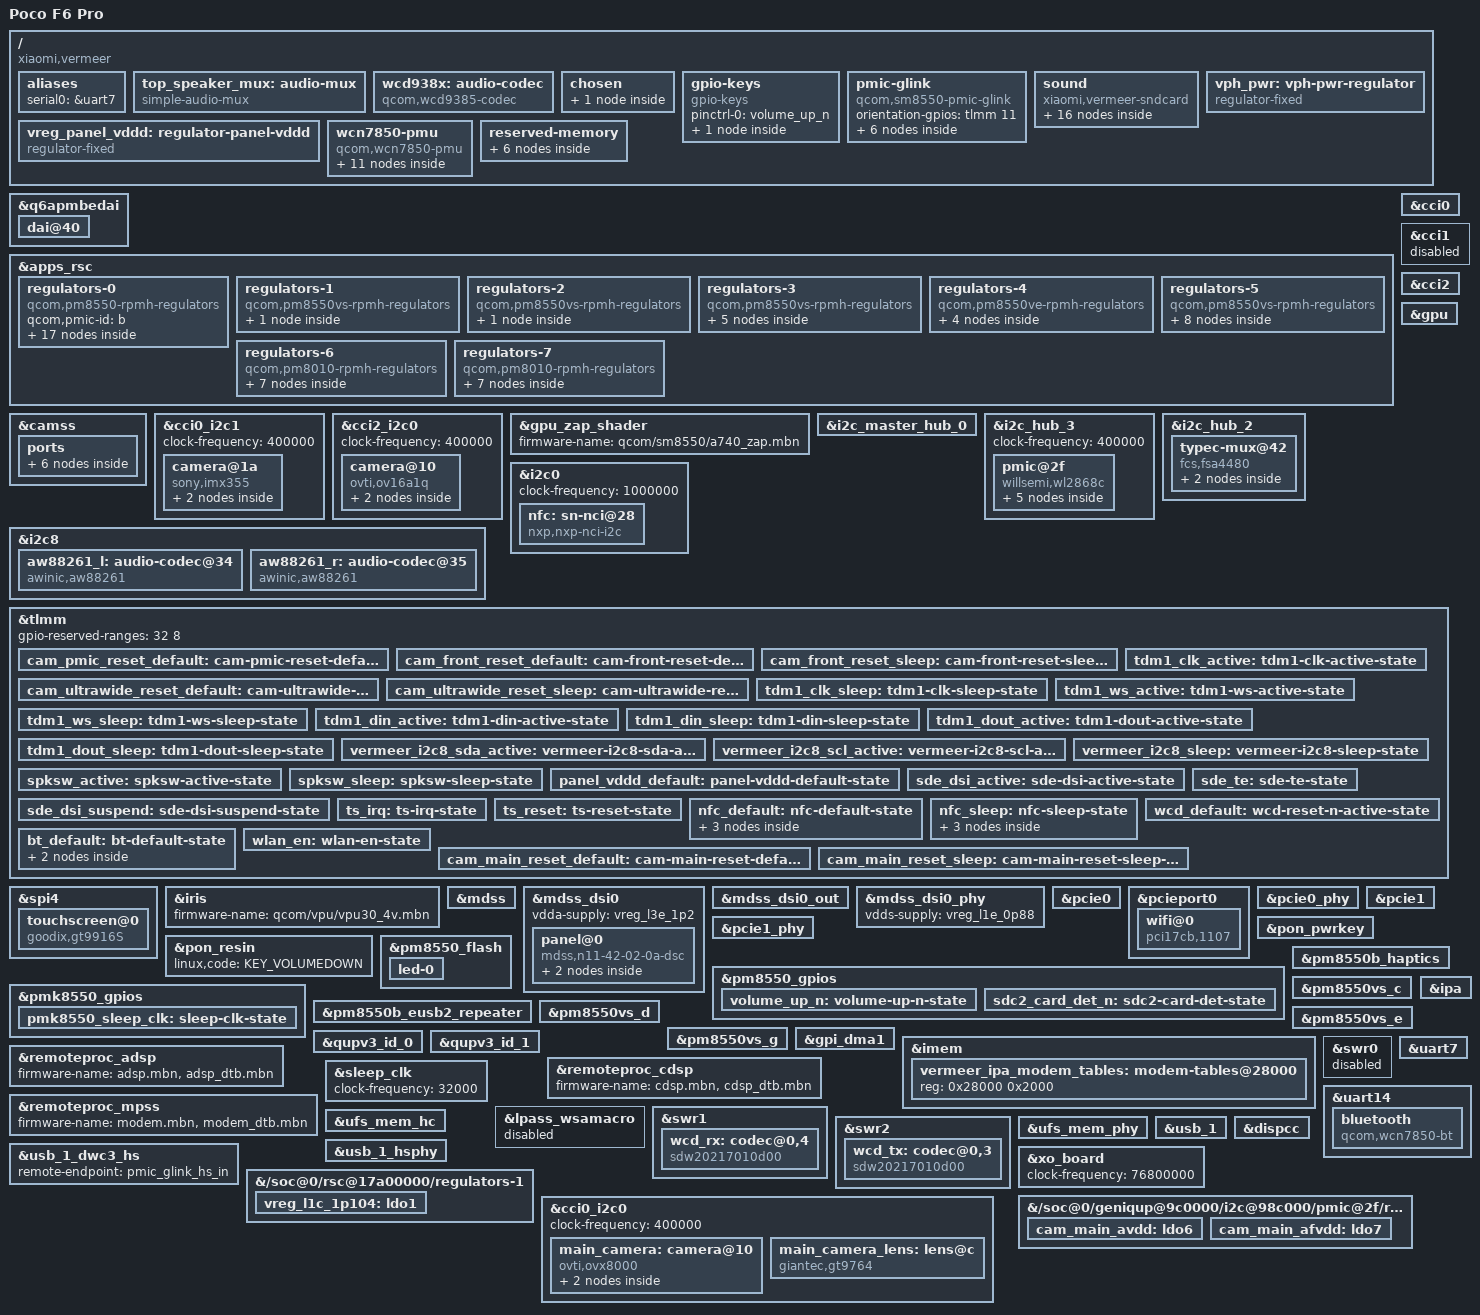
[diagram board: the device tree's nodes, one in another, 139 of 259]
// SPDX-License-Identifier: BSD-3-Clause
/*
 * Copyright (c) 2022, Linaro Limited
 */

/dts-v1/;

#include <dt-bindings/arm/qcom,ids.h>
#include <dt-bindings/clock/qcom,sm8550-camcc.h>
#include <dt-bindings/sound/qcom,q6dsp-lpass-ports.h>
#include <dt-bindings/regulator/qcom,rpmh-regulator.h>
#include "sm8550.dtsi"
#include "pm8010.dtsi"
#include "pm8550.dtsi"
#include "pm8550b.dtsi"
#define PMK8550VE_SID 5
#include "pm8550ve.dtsi"
#include "pm8550vs.dtsi"
#include "pmk8550.dtsi"
#include "pmr735d_a.dtsi"
#include "pmr735d_b.dtsi"
#include <dt-bindings/leds/common.h>
/delete-node/ &adspslpi_mem;

&q6apmbedai {
	#address-cells = <1>;
	#size-cells = <0>;

	dai@40 {
		reg = <SECONDARY_TDM_RX_0>;
		clocks = <&q6prmcc LPASS_CLK_ID_SEC_TDM_IBIT
			  LPASS_CLK_ATTRIBUTE_INVERT_COUPLE_NO>;
		clock-names = "bclk";

		qcom,tdm-sync-mode = <0>;
		qcom,tdm-sync-src = <1>;
		qcom,tdm-data-out = <1>;
		qcom,tdm-invert-sync = <0>;
		qcom,tdm-data-delay = <1>;
		qcom,tdm-data-align = <0>;
	};
};

/ {
	model = "Poco F6 Pro";
	compatible = "xiaomi,vermeer", "qcom,sm8550";
	chassis-type = "handset";

	qcom,msm-id = <QCOM_ID_SM8550 0x20000>;
	qcom,board-id = <0x10008 0>;

	aliases {
		serial0 = &uart7;
	};

	top_speaker_mux: audio-mux {
		compatible = "simple-audio-mux";
		mux-gpios = <&tlmm 68 GPIO_ACTIVE_HIGH>;
		sound-name-prefix = "Top Speaker";
		state-labels = "Speaker", "Receiver";
		idle-state = <0>;
	};

	wcd938x: audio-codec {
		compatible = "qcom,wcd9385-codec";

		pinctrl-names = "default";
		pinctrl-0 = <&wcd_default>;

		qcom,micbias1-microvolt = <2750000>;
		qcom,micbias2-microvolt = <2750000>;
		qcom,micbias3-microvolt = <2750000>;
		qcom,micbias4-microvolt = <2750000>;
		qcom,mbhc-buttons-vthreshold-microvolt = <75000 150000 237000 500000 500000 500000 500000 500000>;
		qcom,mbhc-headset-vthreshold-microvolt = <1700000>;
		qcom,mbhc-headphone-vthreshold-microvolt = <50000>;
		qcom,rx-device = <&wcd_rx>;
		qcom,tx-device = <&wcd_tx>;

		reset-gpios = <&tlmm 108 GPIO_ACTIVE_LOW>;

		vdd-buck-supply = <&vreg_l15b_1p8>;
		vdd-rxtx-supply = <&vreg_l15b_1p8>;
		vdd-io-supply = <&vreg_l15b_1p8>;
		vdd-mic-bias-supply = <&vreg_bob1>;

		#sound-dai-cells = <1>;
	};

	chosen {
		#address-cells = <2>;
		#size-cells = <2>;
		ranges;

		bootargs = "earlycon clk_ignore_unused pd_ignore_unused";
		stdout-path = "serial0:115200n8";

		framebuffer: framebuffer@b8000000 {
			compatible = "simple-framebuffer";
			reg = <0x0 0xb8000000 0x0 0x2b00000>;
			width = <1440>;
			height = <3200>;
			stride = <(1440 * 4)>;
			format = "a8r8g8b8";
		};

	};

	gpio-keys {
		compatible = "gpio-keys";

		pinctrl-0 = <&volume_up_n>;
		pinctrl-names = "default";

		key-volume-up {
			label = "Volume Up";
			linux,code = <KEY_VOLUMEUP>;
			gpios = <&pm8550_gpios 6 GPIO_ACTIVE_LOW>;
			debounce-interval = <32>;
			linux,can-disable;
			wakeup-source;
		};
	};

	pmic-glink {
		compatible = "qcom,sm8550-pmic-glink", "qcom,pmic-glink";
		#address-cells = <1>;
		#size-cells = <0>;
		orientation-gpios = <&tlmm 11 GPIO_ACTIVE_HIGH>;

		connector@0 {
			compatible = "usb-c-connector";
			reg = <0>;
			power-role = "dual";
			data-role = "dual";

			ports {
				#address-cells = <1>;
				#size-cells = <0>;

				port@0 {
					reg = <0>;

					pmic_glink_hs_in: endpoint {
						remote-endpoint = <&usb_1_dwc3_hs>;
					};
				};

				port@2 {
					reg = <2>;

					pmic_glink_sbu: endpoint {
						remote-endpoint = <&fsa4480_sbu_mux>;
					};
				};
			};
		};
	};

	sound {
		compatible = "xiaomi,vermeer-sndcard", "qcom,sm8550-sndcard",
			     "qcom,sm8450-sndcard";
		model = "SM8550-VERMEER";
		aux-devs = <&top_speaker_mux>;
		pinctrl-names = "default", "sleep";
		pinctrl-0 = <&tdm1_clk_active &tdm1_ws_active
				     &tdm1_din_active &tdm1_dout_active
				     &spksw_active>;
		pinctrl-1 = <&tdm1_clk_sleep &tdm1_ws_sleep
				     &tdm1_din_sleep &tdm1_dout_sleep
				     &spksw_sleep>;

		widgets = "Speaker", "Top Speaker",
			  "Speaker", "Bottom Speaker";
		audio-routing = "Top Speaker", "Top Speaker OUT",
				"Top Speaker IN1", "Amplifier L DAC Output",
				"Top Speaker IN2", "Amplifier L DAC Output",
				"Bottom Speaker", "Amplifier R DAC Output",
				"IN1_HPHL", "HPHL_OUT",
				"IN2_HPHR", "HPHR_OUT",
				"AMIC1", "MIC BIAS1",
				"AMIC2", "MIC BIAS2",
				"AMIC3", "MIC BIAS3",
				"AMIC4", "MIC BIAS3",
				"AMIC5", "MIC BIAS4",
				"VA DMIC0", "MIC BIAS1",
				"VA DMIC1", "MIC BIAS1",
				"VA DMIC2", "MIC BIAS3",
				"TX DMIC0", "MIC BIAS1",
				"TX DMIC1", "MIC BIAS2",
				"TX DMIC2", "MIC BIAS3",
				"TX SWR_INPUT0", "ADC1_OUTPUT";

		wcd-playback-dai-link {
			link-name = "WCD Playback";

			cpu {
				sound-dai = <&q6apmbedai RX_CODEC_DMA_RX_0>;
			};

			codec {
				sound-dai = <&wcd938x 0>, <&swr1 0>, <&lpass_rxmacro 0>;
			};

			platform {
				sound-dai = <&q6apm>;
			};
		};

		wcd-capture-dai-link {
			link-name = "WCD Capture";

			cpu {
				sound-dai = <&q6apmbedai TX_CODEC_DMA_TX_3>;
			};

			codec {
				sound-dai = <&wcd938x 1>, <&swr2 0>, <&lpass_txmacro 0>;
			};

			platform {
				sound-dai = <&q6apm>;
			};
		};

		aif-speakers-dai-link {
			link-name = "Secondary TDM0 Playback";

			cpu {
				sound-dai = <&q6apmbedai SECONDARY_TDM_RX_0>;
			};

			codec {
				sound-dai = <&aw88261_r>, <&aw88261_l>;
			};

			platform {
				sound-dai = <&q6apm>;
			};
		};

		va-dai-link {
			link-name = "VA Capture";

			cpu {
				sound-dai = <&q6apmbedai VA_CODEC_DMA_TX_0>;
			};

			codec {
				sound-dai = <&lpass_vamacro 0>;
			};

			platform {
				sound-dai = <&q6apm>;
			};
		};
	};

	vreg_panel_vddd: regulator-panel-vddd {
		compatible = "regulator-fixed";
		regulator-name = "vreg_panel_vddd";
		regulator-min-microvolt = <1070000>;
		regulator-max-microvolt = <1070000>;

		pinctrl-names = "default";
		pinctrl-0 = <&panel_vddd_default>;

		gpio = <&tlmm 42 GPIO_ACTIVE_HIGH>;
		enable-active-high;
		regulator-boot-on;
	};

	vph_pwr: vph-pwr-regulator {
		compatible = "regulator-fixed";
		regulator-name = "vph_pwr";
		regulator-min-microvolt = <3700000>;
		regulator-max-microvolt = <3700000>;

		regulator-always-on;
		regulator-boot-on;
	};

	wcn7850-pmu {
		compatible = "qcom,wcn7850-pmu";

		pinctrl-names = "default";
		pinctrl-0 = <&wlan_en>, <&bt_default>, <&pmk8550_sleep_clk>;

		wlan-enable-gpios = <&tlmm 80 GPIO_ACTIVE_HIGH>;
		bt-enable-gpios = <&tlmm 81 GPIO_ACTIVE_HIGH>;

		vdd-supply = <&vreg_s5g_0p8>;
		vddio-supply = <&vreg_l15b_1p8>;
		vddaon-supply = <&vreg_s2g_0p8>;
		vdddig-supply = <&vreg_s4e_0p9>;
		vddrfa1p2-supply = <&vreg_s4g_1p3>;
		vddrfa1p8-supply = <&vreg_s6g_1p8>;

		regulators {
			vreg_pmu_rfa_cmn: ldo0 {
				regulator-name = "vreg_pmu_rfa_cmn";
			};

			vreg_pmu_aon_0p59: ldo1 {
				regulator-name = "vreg_pmu_aon_0p59";
			};

			vreg_pmu_wlcx_0p8: ldo2 {
				regulator-name = "vreg_pmu_wlcx_0p8";
			};

			vreg_pmu_wlmx_0p85: ldo3 {
				regulator-name = "vreg_pmu_wlmx_0p85";
			};

			vreg_pmu_btcmx_0p85: ldo4 {
				regulator-name = "vreg_pmu_btcmx_0p85";
			};

			vreg_pmu_rfa_0p8: ldo5 {
				regulator-name = "vreg_pmu_rfa_0p8";
			};

			vreg_pmu_rfa_1p2: ldo6 {
				regulator-name = "vreg_pmu_rfa_1p2";
			};

			vreg_pmu_rfa_1p8: ldo7 {
				regulator-name = "vreg_pmu_rfa_1p8";
			};

			vreg_pmu_pcie_0p9: ldo8 {
				regulator-name = "vreg_pmu_pcie_0p9";
			};

			vreg_pmu_pcie_1p8: ldo9 {
				regulator-name = "vreg_pmu_pcie_1p8";
			};
		};
	};

	reserved-memory {

		ramoops@a7000000 {
			compatible = "ramoops";
			reg = <0x0 0xa7000000 0x0 0x400000>;
			console-size = <0x200000>;
			pmsg-size = <0x200000>;
		};

		xbl_dt_log_mem: xbl_dt_log@81a00000 {
			reg = <0x0 0x81a00000 0x0 0x40000>;
			no-map;
		};

		aop_image_mem: aop_image_region@81c00000 {
			reg = <0x0 0x81c00000 0x0 0x60000>;
			no-map;
		};

		xbl_ramdump_mem: xbl_ramdump_region@81200000 {
			reg = <0x0 0x81200000 0x0 0x280000>;
			no-map;
		};

		adspslpi_mem: adspslpi_region@9ea00000 {
			reg = <0x0 0x9ea00000 0x0 0x4680000>;
			no-map;
		};

		splash_memory: splash_region@b8000000 {
			reg = <0x0 0xb8000000 0x0 0x2b00000>;
			no-map;
		};

	};
};

&apps_rsc {
	regulators-0 {
		compatible = "qcom,pm8550-rpmh-regulators";
		qcom,pmic-id = "b";

		// vdd-bob1-supply = <&vph_pwr>;
		// vdd-bob2-supply = <&vph_pwr>;
		// vdd-l1-l4-l10-supply = <&vreg_s6g_1p8>;
		// vdd-l2-l13-l14-supply = <&vreg_bob1>;
		// vdd-l3-supply = <&vreg_s4g_1p3>;
		// vdd-l5-l16-supply = <&vreg_bob1>;
		// vdd-l6-l7-supply = <&vreg_bob1>;
		// vdd-l8-supply = <&vreg_bob1>;
		// vdd-l11-supply = <&vreg_s4g_1p3>;
		// vdd-l12-supply = <&vreg_s6g_1p8>;
		// vdd-l15-supply = <&vreg_s6g_1p8>;
		// vdd-l17-supply = <&vreg_bob2>;

		vreg_bob1: bob1 {
			regulator-name = "vreg_bob1";
			regulator-min-microvolt = <3296000>;
			regulator-max-microvolt = <3960000>;
			regulator-initial-mode = <RPMH_REGULATOR_MODE_HPM>;
		};

		vreg_bob2: bob2 {
			regulator-name = "vreg_bob2";
			regulator-min-microvolt = <2720000>;
			regulator-max-microvolt = <3008000>;
			regulator-initial-mode = <RPMH_REGULATOR_MODE_HPM>;
		};

		vreg_l1b_1p8: ldo1 {
			regulator-name = "vreg_l1b_1p8";
			regulator-min-microvolt = <1800000>;
			regulator-max-microvolt = <1800000>;
			regulator-initial-mode = <RPMH_REGULATOR_MODE_HPM>;
		};

		vreg_l2b_3p0: ldo2 {
			regulator-name = "vreg_l2b_3p0";
			regulator-min-microvolt = <3200000>;
			regulator-max-microvolt = <3200000>;
			regulator-initial-mode = <RPMH_REGULATOR_MODE_HPM>;
		};

		vreg_l4b_3p1: ldo4 {
			regulator-name = "vreg_l4b_1p8";
			regulator-min-microvolt = <1800000>;
			regulator-max-microvolt = <1800000>;
			regulator-initial-mode = <RPMH_REGULATOR_MODE_HPM>;
		};

		vreg_l5b_3p1: ldo5 {
			regulator-name = "vreg_l5b_3p1";
			regulator-min-microvolt = <3104000>;
			regulator-max-microvolt = <3104000>;
			regulator-initial-mode = <RPMH_REGULATOR_MODE_HPM>;
		};

		vreg_l6b_1p8: ldo6 {
			regulator-name = "vreg_l6b_1p8";
			regulator-min-microvolt = <1800000>;
			regulator-max-microvolt = <3008000>;
			regulator-initial-mode = <RPMH_REGULATOR_MODE_HPM>;
		};

		vreg_l7b_1p8: ldo7 {
			regulator-name = "vreg_l7b_1p8";
			regulator-min-microvolt = <1800000>;
			regulator-max-microvolt = <3008000>;
			regulator-initial-mode = <RPMH_REGULATOR_MODE_HPM>;
		};

		vreg_l8b_1p8: ldo8 {
			regulator-name = "vreg_l8b_1p8";
			regulator-min-microvolt = <1800000>;
			regulator-max-microvolt = <1800000>;
			regulator-initial-mode = <RPMH_REGULATOR_MODE_HPM>;
		};

		vreg_l9b_2p9: ldo9 {
			regulator-name = "vreg_l9b_2p9";
			regulator-min-microvolt = <2960000>;
			regulator-max-microvolt = <3300000>;
			regulator-initial-mode = <RPMH_REGULATOR_MODE_HPM>;
			regulator-boot-on;
			regulator-always-on;
		};

		vreg_l11b_1p2: ldo11 {
			regulator-name = "vreg_l11b_1p2";
			regulator-min-microvolt = <1140000>;
			regulator-max-microvolt = <1144000>;
			regulator-initial-mode = <RPMH_REGULATOR_MODE_HPM>;
		};

		vreg_l12b_1p8: ldo12 {
			regulator-name = "vreg_l12b_1p8";
			regulator-min-microvolt = <1800000>;
			regulator-max-microvolt = <1800000>;
			regulator-initial-mode = <RPMH_REGULATOR_MODE_HPM>;
		};

		vreg_l13b_3p0: ldo13 {
			regulator-name = "vreg_l13b_3p0";
			regulator-min-microvolt = <3000000>;
			regulator-max-microvolt = <3000000>;
			regulator-initial-mode = <RPMH_REGULATOR_MODE_HPM>;
		};

		vreg_l14b_3p2: ldo14 {
			regulator-name = "vreg_l14b_3p2";
			regulator-min-microvolt = <3200000>;
			regulator-max-microvolt = <3200000>;
			regulator-initial-mode = <RPMH_REGULATOR_MODE_HPM>;
		};

		vreg_l15b_1p8: ldo15 {
			regulator-name = "vreg_l15b_1p8";
			regulator-min-microvolt = <1800000>;
			regulator-max-microvolt = <1800000>;
			regulator-initial-mode = <RPMH_REGULATOR_MODE_HPM>;
		};

		vreg_l16b_2p8: ldo16 {
			regulator-name = "vreg_l16b_2p8";
			regulator-min-microvolt = <3104000>;
			regulator-max-microvolt = <3104000>;
			regulator-initial-mode = <RPMH_REGULATOR_MODE_HPM>;
		};

		vreg_l17b_2p5: ldo17 {
			regulator-name = "vreg_l17b_2p5";
			regulator-min-microvolt = <2504000>;
			regulator-max-microvolt = <2504000>;
			regulator-initial-mode = <RPMH_REGULATOR_MODE_HPM>;
		};
	};

	regulators-1 {
		compatible = "qcom,pm8550vs-rpmh-regulators";
		qcom,pmic-id = "c";

		vdd-l3-supply = <&vreg_s4e_0p9>;

		vreg_l3c_0p91: ldo3 {
			regulator-name = "vreg_l3c_0p9";
			regulator-min-microvolt = <880000>;
			regulator-max-microvolt = <912000>;
			regulator-initial-mode = <RPMH_REGULATOR_MODE_HPM>;
		};
	};

	regulators-2 {
		compatible = "qcom,pm8550vs-rpmh-regulators";
		qcom,pmic-id = "d";

		vdd-l1-supply = <&vreg_s4e_0p9>;

		vreg_l1d_0p88: ldo1 {
			regulator-name = "vreg_l1d_0p88";
			regulator-min-microvolt = <912000>;
			regulator-max-microvolt = <920000>;
			regulator-initial-mode = <RPMH_REGULATOR_MODE_HPM>;
		};
	};

	regulators-3 {
		compatible = "qcom,pm8550vs-rpmh-regulators";
		qcom,pmic-id = "e";

		vdd-l1-supply = <&vreg_s4e_0p9>;
		vdd-l2-supply = <&vreg_s4e_0p9>;
		vdd-l3-supply = <&vreg_s4g_1p3>;
		vdd-s4-supply = <&vph_pwr>;
		vdd-s5-supply = <&vph_pwr>;

		vreg_s4e_0p9: smps4 {
			regulator-name = "vreg_s4e_0p9";
			regulator-min-microvolt = <904000>;
			regulator-max-microvolt = <984000>;
			regulator-initial-mode = <RPMH_REGULATOR_MODE_HPM>;
		};

		vreg_s5e_1p1: smps5 {
			regulator-name = "vreg_s5e_1p1";
			regulator-min-microvolt = <1010000>;
			regulator-max-microvolt = <1120000>;
			regulator-initial-mode = <RPMH_REGULATOR_MODE_HPM>;
		};

		vreg_l1e_0p88: ldo1 {
			regulator-name = "vreg_l1e_0p88";
			regulator-min-microvolt = <880000>;
			regulator-max-microvolt = <912000>;
			regulator-initial-mode = <RPMH_REGULATOR_MODE_HPM>;
		};

		vreg_l2e_0p9: ldo2 {
			regulator-name = "vreg_l2e_0p9";
			regulator-min-microvolt = <870000>;
			regulator-max-microvolt = <970000>;
			regulator-initial-mode = <RPMH_REGULATOR_MODE_HPM>;
		};

		vreg_l3e_1p2: ldo3 {
			regulator-name = "vreg_l3e_1p2";
			regulator-min-microvolt = <1200000>;
			regulator-max-microvolt = <1200000>;
			regulator-initial-mode = <RPMH_REGULATOR_MODE_HPM>;
		};
	};

	regulators-4 {
		compatible = "qcom,pm8550ve-rpmh-regulators";
		qcom,pmic-id = "f";

		vdd-l1-supply = <&vreg_s4e_0p9>;
		vdd-l2-supply = <&vreg_s4e_0p9>;
		vdd-l3-supply = <&vreg_s4e_0p9>;
		vdd-s4-supply = <&vph_pwr>;

		vreg_s4f_0p5: smps4 {
			regulator-name = "vreg_s4f_0p5";
			regulator-min-microvolt = <300000>;
			regulator-max-microvolt = <700000>;
			regulator-initial-mode = <RPMH_REGULATOR_MODE_HPM>;
		};

		vreg_l1f_0p9: ldo1 {
			regulator-name = "vreg_l1f_0p9";
			regulator-min-microvolt = <880000>;
			regulator-max-microvolt = <912000>;
			regulator-initial-mode = <RPMH_REGULATOR_MODE_HPM>;
		};

		vreg_l2f_0p88: ldo2 {
			regulator-name = "vreg_l2f_0p88";
			regulator-min-microvolt = <880000>;
			regulator-max-microvolt = <912000>;
			regulator-initial-mode = <RPMH_REGULATOR_MODE_HPM>;
		};

		vreg_l3f_0p91: ldo3 {
			regulator-name = "vreg_l3f_0p91";
			regulator-min-microvolt = <880000>;
			regulator-max-microvolt = <912000>;
			regulator-initial-mode = <RPMH_REGULATOR_MODE_HPM>;
		};
	};

	regulators-5 {
		compatible = "qcom,pm8550vs-rpmh-regulators";
		qcom,pmic-id = "g";

		vdd-l1-supply = <&vreg_s4g_1p3>;
		vdd-l2-supply = <&vreg_s4g_1p3>;
		vdd-l3-supply = <&vreg_s4g_1p3>;
		vdd-s1-supply = <&vph_pwr>;
		vdd-s2-supply = <&vph_pwr>;
		vdd-s3-supply = <&vph_pwr>;
		vdd-s4-supply = <&vph_pwr>;
		vdd-s5-supply = <&vph_pwr>;
		vdd-s6-supply = <&vph_pwr>;

		vreg_s1g_1p2: smps1 {
			regulator-name = "vreg_s1g_1p2";
			regulator-min-microvolt = <1200000>;
			regulator-max-microvolt = <1300000>;
			regulator-initial-mode = <RPMH_REGULATOR_MODE_HPM>;
		};

		vreg_s2g_0p8: smps2 {
			regulator-name = "vreg_s2g_0p8";
			regulator-min-microvolt = <500000>;
			regulator-max-microvolt = <1036000>;
			regulator-initial-mode = <RPMH_REGULATOR_MODE_HPM>;
		};

		vreg_s4g_1p3: smps4 {
			regulator-name = "vreg_s4g_1p3";
			regulator-min-microvolt = <1200000>;
			regulator-max-microvolt = <1352000>;
			regulator-initial-mode = <RPMH_REGULATOR_MODE_HPM>;
		};

		vreg_s5g_0p8: smps5 {
			regulator-name = "vreg_s5g_0p8";
			regulator-min-microvolt = <500000>;
			regulator-max-microvolt = <1004000>;
			regulator-initial-mode = <RPMH_REGULATOR_MODE_HPM>;
		};

		vreg_s6g_1p8: smps6 {
			regulator-name = "vreg_s6g_1p8";
			regulator-min-microvolt = <1800000>;
			regulator-max-microvolt = <2000000>;
			regulator-initial-mode = <RPMH_REGULATOR_MODE_HPM>;
		};

		vreg_l1g_1p2: ldo1 {
			regulator-name = "vreg_l1g_1p2";
			regulator-min-microvolt = <1144000>;
			regulator-max-microvolt = <1256000>;
			regulator-initial-mode = <RPMH_REGULATOR_MODE_HPM>;
		};

		vreg_l2g_1p2: ldo2 {
			regulator-name = "vreg_l2g_1p2";
			regulator-min-microvolt = <1100000>;
			regulator-max-microvolt = <1200000>;
			regulator-initial-mode = <RPMH_REGULATOR_MODE_HPM>;
		};

		vreg_l3g_1p2: ldo3 {
			regulator-name = "vreg_l3g_1p2";
			regulator-min-microvolt = <1200000>;
			regulator-max-microvolt = <1200000>;
			regulator-initial-mode = <RPMH_REGULATOR_MODE_HPM>;
		};
	};

	regulators-6 {
		compatible = "qcom,pm8010-rpmh-regulators";
		qcom,pmic-id = "m";

		vdd-l1-l2-supply = <&vreg_s4g_1p3>;
		vdd-l3-l4-supply = <&vreg_bob2>;
		vdd-l5-supply = <&vreg_s6g_1p8>;
		vdd-l6-supply = <&vreg_s6g_1p8>;
		vdd-l7-supply = <&vreg_bob1>;

		vreg_l1m_1p056: ldo1 {
			regulator-name = "vreg_l1m_1p056";
			regulator-min-microvolt = <1056000>;
			regulator-max-microvolt = <1056000>;
			regulator-initial-mode = <RPMH_REGULATOR_MODE_HPM>;
		};

		vreg_l2m_1p056: ldo2 {
			regulator-name = "vreg_l2m_1p056";
			regulator-min-microvolt = <1056000>;
			regulator-max-microvolt = <1056000>;
			regulator-initial-mode = <RPMH_REGULATOR_MODE_HPM>;
		};

		vreg_l3m_2p8: ldo3 {
			regulator-name = "vreg_l3m_2p8";
			regulator-min-microvolt = <2800000>;
			regulator-max-microvolt = <2800000>;
			regulator-initial-mode = <RPMH_REGULATOR_MODE_HPM>;
		};

		vreg_l4m_2p8: ldo4 {
			regulator-name = "vreg_l4m_2p8";
			regulator-min-microvolt = <2800000>;
			regulator-max-microvolt = <2800000>;
			regulator-initial-mode = <RPMH_REGULATOR_MODE_HPM>;
		};

		vreg_l5m_1p8: ldo5 {
			regulator-name = "vreg_l5m_1p8";
			regulator-min-microvolt = <1800000>;
			regulator-max-microvolt = <1800000>;
			regulator-initial-mode = <RPMH_REGULATOR_MODE_HPM>;
		};

		vreg_l6m_1p8: ldo6 {
			regulator-name = "vreg_l6m_1p8";
			regulator-min-microvolt = <1800000>;
			regulator-max-microvolt = <1800000>;
			regulator-initial-mode = <RPMH_REGULATOR_MODE_HPM>;
		};

		vreg_l7m_2p9: ldo7 {
			regulator-name = "vreg_l7m_2p9";
			regulator-min-microvolt = <2800000>;
			regulator-max-microvolt = <2904000>;
			regulator-initial-mode = <RPMH_REGULATOR_MODE_HPM>;
		};
	};

	regulators-7 {
		compatible = "qcom,pm8010-rpmh-regulators";
		qcom,pmic-id = "n";

		vdd-l1-l2-supply = <&vreg_s4g_1p3>;
		vdd-l3-l4-supply = <&vreg_bob2>;
		vdd-l5-supply = <&vreg_s6g_1p8>;
		vdd-l6-supply = <&vreg_bob1>;
		vdd-l7-supply = <&vreg_bob1>;

		vreg_l1n_1p1: ldo1 {
			regulator-name = "vreg_l1n_1p1";
			regulator-min-microvolt = <1104000>;
			regulator-max-microvolt = <1104000>;
			regulator-initial-mode = <RPMH_REGULATOR_MODE_HPM>;
		};

		vreg_l2n_1p1: ldo2 {
			regulator-name = "vreg_l2n_1p1";
			regulator-min-microvolt = <1104000>;
			regulator-max-microvolt = <1104000>;
			regulator-initial-mode = <RPMH_REGULATOR_MODE_HPM>;
		};

		vreg_l3n_2p8: ldo3 {
			regulator-name = "vreg_l3n_2p8";
			regulator-min-microvolt = <2800000>;
			regulator-max-microvolt = <2800000>;
			regulator-initial-mode = <RPMH_REGULATOR_MODE_HPM>;
		};

		vreg_l4n_2p8: ldo4 {
			regulator-name = "vreg_l4n_2p8";
			regulator-min-microvolt = <2800000>;
			regulator-max-microvolt = <2800000>;
			regulator-initial-mode = <RPMH_REGULATOR_MODE_HPM>;
		};

		vreg_l5n_1p8: ldo5 {
			regulator-name = "vreg_l5n_1p8";
			regulator-min-microvolt = <1800000>;
			regulator-max-microvolt = <1800000>;
			regulator-initial-mode = <RPMH_REGULATOR_MODE_HPM>;
		};

		vreg_l6n_3p3: ldo6 {
			regulator-name = "vreg_l6n_3p3";
			regulator-min-microvolt = <3304000>;
			regulator-max-microvolt = <3304000>;
			regulator-initial-mode = <RPMH_REGULATOR_MODE_HPM>;
		};

		vreg_l7n_2p96: ldo7 {
			regulator-name = "vreg_l7n_2p96";
			regulator-min-microvolt = <2960000>;
			regulator-max-microvolt = <2960000>;
			regulator-initial-mode = <RPMH_REGULATOR_MODE_HPM>;
		};
	};
};

&camss {
	vdda-phy-supply = <&vreg_l1e_0p88>;
	vdda-pll-supply = <&vreg_l3e_1p2>;
	status = "okay";

	ports {
		port@2 {
			reg = <2>;

			csiphy2_ep: endpoint {
				clock-lanes = <4>;
				data-lanes = <0 1 2 3>;
				remote-endpoint = <&imx355_ep>;
			};
		};

		port@4 {
			reg = <4>;

			csiphy4_ep: endpoint {
				clock-lanes = <4>;
				data-lanes = <0 1 2 3>;
				remote-endpoint = <&ov16a1q_ep>;
			};
		};
	};
};

&cci0 {
	pinctrl-0 = <&cci0_1_default>;
	pinctrl-1 = <&cci0_1_sleep>;
	status = "okay";
};

&cci0_i2c1 {
	clock-frequency = <400000>;

	camera@1a {
		compatible = "sony,imx355";
		reg = <0x1a>;

		clocks = <&camcc CAM_CC_MCLK1_CLK>;
		assigned-clocks = <&camcc CAM_CC_MCLK1_CLK>;
		assigned-clock-rates = <19200000>;

		reset-gpios = <&tlmm 117 GPIO_ACTIVE_LOW>;
		pinctrl-names = "default", "sleep";
		pinctrl-0 = <&cam1_default &cam_ultrawide_reset_default>;
		pinctrl-1 = <&cam1_sleep &cam_ultrawide_reset_sleep>;

		avdd-supply = <&cam_ultrawide_avdd>;
		dvdd-supply = <&cam_ultrawide_dvdd>;
		dovdd-supply = <&vreg_l8b_1p8>;

		orientation = <1>;
		rotation = <270>;

		port {
			imx355_ep: endpoint {
				data-lanes = <1 2 3 4>;
				link-frequencies = /bits/ 64 <360000000>;
				remote-endpoint = <&csiphy2_ep>;
			};
		};
	};
};

&cci1 {
	status = "disabled";
};

&cci2 {
	pinctrl-0 = <&cci2_0_default>;
	pinctrl-1 = <&cci2_0_sleep>;
	status = "okay";
};

&cci2_i2c0 {
	clock-frequency = <400000>;

	camera@10 {
		compatible = "ovti,ov16a1q";
		reg = <0x10>;

		clocks = <&camcc CAM_CC_MCLK0_CLK>;
		assigned-clocks = <&camcc CAM_CC_MCLK0_CLK>;
		assigned-clock-rates = <19200000>;

		reset-gpios = <&tlmm 120 GPIO_ACTIVE_LOW>;
		pinctrl-names = "default", "sleep";
		pinctrl-0 = <&cam0_default &cam_front_reset_default>;
		pinctrl-1 = <&cam0_sleep &cam_front_reset_sleep>;

		avdd-supply = <&cam_front_avdd>;
		dvdd-supply = <&cam_front_dvdd>;
		dovdd-supply = <&vreg_l8b_1p8>;
		orientation = <0>;
		rotation = <90>;

		port {
			ov16a1q_ep: endpoint {
				data-lanes = <1 2 3 4>;
				link-frequencies = /bits/ 64 <696000000>;
				remote-endpoint = <&csiphy4_ep>;
			};
		};
	};
};

&gpu {
	status = "okay";
};

&gpu_zap_shader {
	firmware-name = "qcom/sm8550/a740_zap.mbn";
};

&i2c_master_hub_0 {
	status = "okay";
};

&i2c_hub_3 {
	clock-frequency = <400000>;
	status = "okay";

	pmic@2f {
		compatible = "willsemi,wl2868c";
		reg = <0x2f>;
		reset-gpios = <&tlmm 126 GPIO_ACTIVE_LOW>;
		pinctrl-names = "default";
		pinctrl-0 = <&cam_pmic_reset_default>;

		regulators {
			cam_front_dvdd: ldo1 {
				regulator-name = "cam_front_dvdd";
				regulator-min-microvolt = <1200000>;
				regulator-max-microvolt = <1200000>;
			};

			cam_ultrawide_dvdd: ldo2 {
				regulator-name = "cam_ultrawide_dvdd";
				regulator-min-microvolt = <1200000>;
				regulator-max-microvolt = <1200000>;
			};

			cam_ultrawide_avdd: ldo3 {
				regulator-name = "cam_ultrawide_avdd";
				regulator-min-microvolt = <2700000>;
				regulator-max-microvolt = <2704000>;
			};

			cam_front_avdd: ldo5 {
				regulator-name = "cam_front_avdd";
				regulator-min-microvolt = <2800000>;
				regulator-max-microvolt = <2800000>;
			};
		};
	};
};

&i2c_hub_2 {
	status = "okay";

	typec-mux@42 {
		compatible = "fcs,fsa4480";
		reg = <0x42>;

		vcc-supply = <&vreg_bob1>;

		mode-switch;
		orientation-switch;

		port {
			fsa4480_sbu_mux: endpoint {
				remote-endpoint = <&pmic_glink_sbu>;
			};
		};
	};
};

&i2c0 {
	clock-frequency = <1000000>;
	status = "okay";

	nfc: sn-nci@28 {
		compatible = "nxp,nxp-nci-i2c";
		reg = <0x28>;

		enable-gpios = <&tlmm 30 GPIO_ACTIVE_HIGH>;
		firmware-gpios = <&tlmm 12 GPIO_ACTIVE_HIGH>;

		interrupt-parent = <&tlmm>;
		interrupts = <55 0>;

		pinctrl-names = "default", "sleep";
		pinctrl-0 = <&nfc_default>;
		pinctrl-1 = <&nfc_sleep>;
	};
};

&i2c8 {
	/*
	 * On Vermeer QUPv3 SE8 is routed to GPIO0/1 (the "mirb" pads),
	 * not to GPIO56/57 used by the reference SM8550 boards.
	 */
	clock-frequency = <400000>;
	pinctrl-names = "default", "sleep";
	pinctrl-0 = <&vermeer_i2c8_sda_active &vermeer_i2c8_scl_active>;
	pinctrl-1 = <&vermeer_i2c8_sleep>;
	status = "okay";

	/* Top speaker / ear speaker */
	aw88261_l: audio-codec@34 {
		compatible = "awinic,aw88261";
		reg = <0x34>;

		dvdd-supply = <&vreg_l15b_1p8>;
		reset-gpios = <&tlmm 182 GPIO_ACTIVE_HIGH>;
		sound-name-prefix = "Amplifier L";
		firmware-name = "qcom/sm8550/aw882xx_acf.bin";

		awinic,audio-channel = <0>;
		awinic,sync-flag;

		#sound-dai-cells = <0>;
	};

	/* Bottom speaker */
	aw88261_r: audio-codec@35 {
		compatible = "awinic,aw88261";
		reg = <0x35>;

		dvdd-supply = <&vreg_l15b_1p8>;
		reset-gpios = <&tlmm 183 GPIO_ACTIVE_HIGH>;
		sound-name-prefix = "Amplifier R";
		firmware-name = "qcom/sm8550/aw882xx_acf.bin";

		awinic,audio-channel = <1>;
		awinic,sync-flag;

		#sound-dai-cells = <0>;
	};
};

&tlmm {
	cam_pmic_reset_default: cam-pmic-reset-default-state {
		pins = "gpio126";
		function = "gpio";
		drive-strength = <2>;
		bias-disable;
	};

	cam_front_reset_default: cam-front-reset-default-state {
		pins = "gpio120";
		function = "gpio";
		drive-strength = <2>;
		bias-disable;
	};

	cam_front_reset_sleep: cam-front-reset-sleep-state {
		pins = "gpio120";
		function = "gpio";
		drive-strength = <2>;
		bias-pull-down;
	};

	cam_ultrawide_reset_default: cam-ultrawide-reset-default-state {
		pins = "gpio117";
		function = "gpio";
		drive-strength = <2>;
		bias-disable;
	};

	cam_ultrawide_reset_sleep: cam-ultrawide-reset-sleep-state {
		pins = "gpio117";
		function = "gpio";
		drive-strength = <2>;
		bias-pull-down;
	};
};

&spi4 {
	status = "okay";

	touchscreen@0 {
		compatible = "goodix,gt9916S", "goodix,gt9916";
		reg = <0>;

		interrupt-parent = <&tlmm>;
		interrupts = <25 IRQ_TYPE_EDGE_FALLING>;

		reset-gpios = <&tlmm 24 GPIO_ACTIVE_LOW>;

		avdd-supply = <&vreg_l2b_3p0>;
		vddio-supply = <&vreg_l12b_1p8>;

		spi-max-frequency = <15000000>;

		touchscreen-size-x = <1440>;
		touchscreen-size-y = <3200>;

		pinctrl-names = "default";
		pinctrl-0 = <&ts_irq>, <&ts_reset>;
	};
};

&iris {
	status = "okay";
	firmware-name = "qcom/vpu/vpu30_4v.mbn";
};

/* GPIO68 is the speaker switch wired only to the top AW88261. */
&tlmm {
	/* Secondary MI2S is routed to the external speaker amps on these TLMM pins. */
	tdm1_clk_active: tdm1-clk-active-state {
		pins = "gpio121";
		function = "i2s1_sck";
		drive-strength = <8>;
		bias-disable;
		output-high;
	};

	tdm1_clk_sleep: tdm1-clk-sleep-state {
		pins = "gpio121";
		function = "gpio";
		drive-strength = <2>;
		bias-pull-down;
		input-enable;
	};

	tdm1_ws_active: tdm1-ws-active-state {
		pins = "gpio123";
		function = "i2s1_ws";
		drive-strength = <8>;
		bias-disable;
		output-high;
	};

	tdm1_ws_sleep: tdm1-ws-sleep-state {
		pins = "gpio123";
		function = "gpio";
		drive-strength = <2>;
		bias-pull-down;
		input-enable;
	};

	tdm1_din_active: tdm1-din-active-state {
		pins = "gpio122";
		function = "i2s1_data0";
		drive-strength = <8>;
		bias-disable;
	};

	tdm1_din_sleep: tdm1-din-sleep-state {
		pins = "gpio122";
		function = "gpio";
		drive-strength = <2>;
		bias-pull-down;
		input-enable;
	};

	tdm1_dout_active: tdm1-dout-active-state {
		pins = "gpio124";
		function = "i2s1_data1";
		drive-strength = <8>;
		bias-disable;
	};

	tdm1_dout_sleep: tdm1-dout-sleep-state {
		pins = "gpio124";
		function = "gpio";
		drive-strength = <2>;
		bias-pull-down;
		input-enable;
	};

	vermeer_i2c8_sda_active: vermeer-i2c8-sda-active-state {
		pins = "gpio0";
		function = "qup2_se0_l0_mirb";
		drive-strength = <2>;
		bias-pull-up;
	};

	vermeer_i2c8_scl_active: vermeer-i2c8-scl-active-state {
		pins = "gpio1";
		function = "qup2_se0_l1_mirb";
		drive-strength = <2>;
		bias-pull-up;
	};

	vermeer_i2c8_sleep: vermeer-i2c8-sleep-state {
		pins = "gpio0", "gpio1";
		function = "gpio";
		drive-strength = <2>;
		bias-disable;
	};

	spksw_active: spksw-active-state {
		pins = "gpio68";
		function = "gpio";
		drive-strength = <2>;
		bias-disable;
		/* The mux driver selects Receiver=1 only for handset calls. */
		output-low;
	};

	spksw_sleep: spksw-sleep-state {
		pins = "gpio68";
		function = "gpio";
		drive-strength = <2>;
		bias-pull-down;
		output-low;
	};
};

&mdss {
	status = "okay";
};

&mdss_dsi0 {
	vdda-supply = <&vreg_l3e_1p2>;
	status = "okay";

	panel@0 {
		compatible = "mdss,n11-42-02-0a-dsc";
		reg = <0>;

		pinctrl-names = "default", "sleep";
		pinctrl-0 = <&sde_dsi_active>, <&sde_te>;
		pinctrl-1 = <&sde_dsi_suspend>, <&sde_te>;

		vddio-supply = <&vreg_l4b_3p1>;
		vddd-supply = <&vreg_panel_vddd>;
		vci-supply = <&vreg_l13b_3p0>;
		vdd-supply = <&vreg_l11b_1p2>;

		reset-gpios = <&tlmm 133 GPIO_ACTIVE_HIGH>;
		te-gpios = <&tlmm 86 GPIO_ACTIVE_HIGH>;

		port {
			panel0_in: endpoint {
				remote-endpoint = <&mdss_dsi0_out>;
			};
		};
	};
};

&mdss_dsi0_out {
	remote-endpoint = <&panel0_in>;
	data-lanes = <0 1 2 3>;
};

&mdss_dsi0_phy {
	vdds-supply = <&vreg_l1e_0p88>;
	status = "okay";
};


&pcie0 {
	wake-gpios = <&tlmm 96 GPIO_ACTIVE_HIGH>;
	perst-gpios = <&tlmm 94 GPIO_ACTIVE_LOW>;

	pinctrl-names = "default";
	pinctrl-0 = <&pcie0_default_state>;

	status = "okay";
};

&pcieport0 {
	wifi@0 {
		compatible = "pci17cb,1107";
		reg = <0x10000 0x0 0x0 0x0 0x0>;

		vddrfacmn-supply = <&vreg_pmu_rfa_cmn>;
		vddaon-supply = <&vreg_pmu_aon_0p59>;
		vddwlcx-supply = <&vreg_pmu_wlcx_0p8>;
		vddwlmx-supply = <&vreg_pmu_wlmx_0p85>;
		vddrfa0p8-supply = <&vreg_pmu_rfa_0p8>;
		vddrfa1p2-supply = <&vreg_pmu_rfa_1p2>;
		vddrfa1p8-supply = <&vreg_pmu_rfa_1p8>;
		vddpcie0p9-supply = <&vreg_pmu_pcie_0p9>;
		vddpcie1p8-supply = <&vreg_pmu_pcie_1p8>;
	};
};

&pcie0_phy {
	vdda-phy-supply = <&vreg_l1e_0p88>;
	vdda-pll-supply = <&vreg_l3e_1p2>;

	status = "okay";
};

&pcie1 {
	wake-gpios = <&tlmm 99 GPIO_ACTIVE_HIGH>;
	perst-gpios = <&tlmm 97 GPIO_ACTIVE_LOW>;

	pinctrl-names = "default";
	pinctrl-0 = <&pcie1_default_state>;

	status = "okay";
};

&pcie1_phy {
	vdda-phy-supply = <&vreg_l3c_0p91>;
	vdda-pll-supply = <&vreg_l3e_1p2>;
	vdda-qref-supply = <&vreg_l1e_0p88>;

	status = "okay";
};

&pon_pwrkey {
	status = "okay";
};

&pon_resin {
	linux,code = <KEY_VOLUMEDOWN>;

	status = "okay";
};

&pm8550_flash {
	status = "okay";

	led-0 {
		function = LED_FUNCTION_FLASH;
		color = <LED_COLOR_ID_WHITE>;
		led-sources = <1>;
		led-max-microamp = <500000>;
		flash-max-microamp = <2000000>;
		flash-max-timeout-us = <1280000>;
		function-enumerator = <0>;
	};
};

&pm8550_gpios {
	volume_up_n: volume-up-n-state {
		pins = "gpio6";
		function = "normal";
		power-source = <1>;
		bias-pull-up;
		input-enable;
	};

	sdc2_card_det_n: sdc2-card-det-state {
		pins = "gpio12";
		function = "normal";
		input-enable;
		output-disable;
		bias-pull-up;
		power-source = <1>; /* 1.8 V */
	};
};

&pmk8550_gpios {
	pmk8550_sleep_clk: sleep-clk-state {
		pins = "gpio3";
		function = "func1";
		input-disable;
		output-enable;
		bias-disable;
		power-source = <0>;
	};
};

&pm8550b_eusb2_repeater {
	qcom,tune-usb2-preem = /bits/ 8 <0x7>;
	qcom,tune-usb2-disc-thres = /bits/ 8 <0x7>;
	qcom,tune-usb2-amplitude = /bits/ 8 <0xf>;
	vdd18-supply = <&vreg_l15b_1p8>;
	vdd3-supply = <&vreg_l5b_3p1>;
};

&pm8550b_haptics {
	/* Board limits and nominal LRA period from the stock Vermeer DT. */
	qcom,vmax-microvolt = <1400000>;
	qcom,custom-vmax-microvolt = <8500000>;
	qcom,lra-period-us = <5880>;
	status = "okay";
};

&pm8550vs_c {
	status = "okay";
};

&pm8550vs_d {
	status = "okay";
};

&pm8550vs_e {
	status = "okay";
};

&pm8550vs_g {
	status = "okay";
};

&gpi_dma1 {
	status = "okay";
};

&ipa {
	sram = <&vermeer_ipa_modem_tables>;
	qcom,gsi-loader = "self";
	memory-region = <&ipa_fw_mem>;
	firmware-name = "ipa_fws.mbn";
	status = "okay";
};

&imem {
	/* Match the modem-table range in kalama-ipa.dtsi. */
	vermeer_ipa_modem_tables: modem-tables@28000 {
		reg = <0x28000 0x2000>;
	};
};

&qupv3_id_0 {
	status = "okay";
};

&qupv3_id_1 {
	status = "okay";
};

&remoteproc_adsp {
	firmware-name = "adsp.mbn",
			"adsp_dtb.mbn";
	status = "okay";
};

&remoteproc_cdsp {
	firmware-name = "cdsp.mbn",
			"cdsp_dtb.mbn";
	status = "okay";
};

&remoteproc_mpss {
	firmware-name = "modem.mbn",
			"modem_dtb.mbn";
	status = "okay";
};

&sleep_clk {
	clock-frequency = <32000>;
};

&swr0 {
	status = "disabled";
};

&lpass_wsamacro {
	status = "disabled";
};

&swr1 {
	status = "okay";

	/* WCD9385 RX */
	wcd_rx: codec@0,4 {
		compatible = "sdw20217010d00";
		reg = <0 4>;
		qcom,rx-port-mapping = <1 2 3 4 5>;
	};
};

&swr2 {
	status = "okay";

	/* Active Android recorder: slave ADC ports 1/2 use lanes 1/2,
	 * sample interval 4 and offset 0. They map to master TX2/TX3.
	 * Qualcomm's transport parameters are indexed by MASTER port.
	 */
	qcom,ports-sinterval-low = /bits/ 8 <0x01 0x03 0x03 0x03>;
	qcom,ports-offset1 = /bits/ 8 <0x00 0x00 0x00 0x01>;
	qcom,ports-lane-control = /bits/ 8 <0x01 0x01 0x02 0x00>;

	/* WCD9385 TX */
	wcd_tx: codec@0,3 {
		compatible = "sdw20217010d00";
		reg = <0 3>;
		/* ADC1/2 -> master TX2; ADC3/4 -> master TX3, as on Android.
		 * DMIC ports are unused by the built-in analog microphone pair.
		 */
		qcom,tx-port-mapping = <2 3 3 4>;
	};
};

&tlmm {
	gpio-reserved-ranges = <32 8>;

	panel_vddd_default: panel-vddd-default-state {
		pins = "gpio42";
		function = "gpio";
		drive-strength = <8>;
		bias-pull-up;
	};

	sde_dsi_active: sde-dsi-active-state {
		pins = "gpio133";
		function = "gpio";
		drive-strength = <8>;
		bias-disable;
	};

	sde_dsi_suspend: sde-dsi-suspend-state {
		pins = "gpio133";
		function = "gpio";
		drive-strength = <2>;
		bias-pull-down;
	};

	sde_te: sde-te-state {
		pins = "gpio86";
		function = "mdp_vsync";
		drive-strength = <2>;
		bias-pull-down;
	};

	ts_irq: ts-irq-state {
		pins = "gpio25";
		function = "gpio";
		drive-strength = <8>;
		bias-pull-up;
	};

	ts_reset: ts-reset-state {
		pins = "gpio24";
		function = "gpio";
		drive-strength = <8>;
		bias-pull-up;
	};

	nfc_default: nfc-default-state {
		nfc_int_active: nfc_int_active-state {
			pins = "gpio55";
			function = "gpio";
			drive-strength = <2>;
			bias-pull-down;
		};

		nfc_enable_active: nfc_enable_active-state {
			pins = "gpio30";
			function = "gpio";
			drive-strength = <2>;
			bias-disable;
		};

		nfc_clk_req_active: nfc_clk_req_active-state {
			pins = "gpio31";
			function = "gpio";
			drive-strength = <2>;
			bias-disable;
		};
	};

	nfc_sleep: nfc-sleep-state {
		nfc_int_suspend: nfc_int_suspend-state {
			pins = "gpio55";
			function = "gpio";
			drive-strength = <2>;
			bias-pull-down;
		};

		nfc_enable_suspend: nfc_enable_suspend-state {
			pins = "gpio30";
			function = "gpio";
			drive-strength = <2>;
			bias-disable;
		};

		nfc_clk_req_suspend: nfc_clk_req_suspend-state {
			pins = "gpio31";
			function = "gpio";
			drive-strength = <2>;
			bias-disable;
		};
	};

	wcd_default: wcd-reset-n-active-state {
		pins = "gpio108";
		function = "gpio";
		drive-strength = <16>;
		bias-disable;
		output-low;
	};

	bt_default: bt-default-state {
		bt-en-pins {
			pins = "gpio81";
			function = "gpio";
			drive-strength = <16>;
			bias-disable;
		};

		sw-ctrl-pins {
			pins = "gpio82";
			function = "gpio";
			bias-pull-down;
		};
	};

	wlan_en: wlan-en-state {
		pins = "gpio80";
		function = "gpio";
		drive-strength = <8>;
		bias-pull-down;
	};
};

&uart7 {
	status = "okay";
};

&uart14 {
	status = "okay";

	bluetooth {
		compatible = "qcom,wcn7850-bt";

		local-bd-address = [ 24 00 00 00 5a ad ];

		vddrfacmn-supply = <&vreg_pmu_rfa_cmn>;
		vddaon-supply = <&vreg_pmu_aon_0p59>;
		vddwlcx-supply = <&vreg_pmu_wlcx_0p8>;
		vddwlmx-supply = <&vreg_pmu_wlmx_0p85>;
		vddrfa0p8-supply = <&vreg_pmu_rfa_0p8>;
		vddrfa1p2-supply = <&vreg_pmu_rfa_1p2>;
		vddrfa1p8-supply = <&vreg_pmu_rfa_1p8>;

		max-speed = <3200000>;
	};
};

&ufs_mem_hc {
	reset-gpios = <&tlmm 210 GPIO_ACTIVE_LOW>;
	vcc-supply = <&vreg_l17b_2p5>;
	vcc-max-microamp = <1300000>;
	vccq-supply = <&vreg_l1g_1p2>;
	vccq-max-microamp = <1200000>;
	vdd-hba-supply = <&vreg_l3g_1p2>;

	status = "okay";
};

&ufs_mem_phy {
	vdda-phy-supply = <&vreg_l1d_0p88>;
	vdda-pll-supply = <&vreg_l3e_1p2>;

	status = "okay";
};

&usb_1 {
	/* Keep USB 2.0 only for now */
	qcom,select-utmi-as-pipe-clk;

	dr_mode = "otg";
	usb-role-switch;
	maximum-speed = "high-speed";
	/* Remove USB3 phy */
	phys = <&usb_1_hsphy>;
	phy-names = "usb2-phy";

	status = "okay";
};

&usb_1_dwc3_hs {
	remote-endpoint = <&pmic_glink_hs_in>;
};

&usb_1_hsphy {
	vdd-supply = <&vreg_l1e_0p88>;
	vdda12-supply = <&vreg_l3e_1p2>;

	phys = <&pm8550b_eusb2_repeater>;

	status = "okay";
};

&xo_board {
	clock-frequency = <76800000>;
};


&dispcc {
	status = "okay";
};

&{/soc@0/rsc@17a00000/regulators-1} {
	vreg_l1c_1p104: ldo1 {
		regulator-name = "vreg_l1c_1p104";
		regulator-min-microvolt = <1104000>;
		regulator-max-microvolt = <1104000>;
		regulator-initial-mode = <RPMH_REGULATOR_MODE_HPM>;
	};
};

&{/soc@0/geniqup@9c0000/i2c@98c000/pmic@2f/regulators} {
	cam_main_avdd: ldo6 {
		regulator-name = "cam_main_avdd";
		regulator-min-microvolt = <2800000>;
		regulator-max-microvolt = <2800000>;
	};

	cam_main_afvdd: ldo7 {
		regulator-name = "cam_main_afvdd";
		regulator-min-microvolt = <3104000>;
		regulator-max-microvolt = <3104000>;
	};
};

&cci0 {
	pinctrl-0 = <&cci0_0_default &cci0_1_default>;
	pinctrl-1 = <&cci0_0_sleep &cci0_1_sleep>;
};

&cci0_i2c0 {
	clock-frequency = <400000>;

	main_camera: camera@10 {
		compatible = "ovti,ovx8000";
		reg = <0x10>;
		clocks = <&camcc CAM_CC_MCLK2_CLK>;
		assigned-clocks = <&camcc CAM_CC_MCLK2_CLK>;
		assigned-clock-rates = <19200000>;
		reset-gpios = <&tlmm 118 GPIO_ACTIVE_LOW>;
		pinctrl-names = "default", "sleep";
		pinctrl-0 = <&cam2_default &cam_main_reset_default>;
		pinctrl-1 = <&cam2_sleep &cam_main_reset_sleep>;

		afvdd-supply = <&cam_main_afvdd>;
		avdd-supply = <&cam_main_avdd>;
		dovdd-supply = <&vreg_l8b_1p8>;
		dvdd-supply = <&vreg_l1c_1p104>;
		lens-focus = <&main_camera_lens>;
		orientation = <1>;
		rotation = <270>;

		port {
			ovx8000_ep: endpoint {
				bus-type = <1>;
				data-lanes = <0 1 2>;
				link-frequencies = /bits/ 64 <1348800000>;
				remote-endpoint = <&csiphy5_ep>;
			};
		};
	};

	main_camera_lens: lens@c {
		compatible = "giantec,gt9764";
		reg = <0x0c>;
		vin-supply = <&vreg_l8b_1p8>;
		vdd-supply = <&cam_main_afvdd>;
		/* AAC GT9764: Android registers 0x06=0x40, 0x07=0x07. */
		dongwoon,aac-mode = <2>;
		dongwoon,clock-presc = <0>;
		dongwoon,aac-timing = <7>;
	};
};

&camss {
	ports {
		port@5 {
			reg = <5>;
			csiphy5_ep: endpoint {
				bus-type = <1>;
				data-lanes = <0 1 2>;
				remote-endpoint = <&ovx8000_ep>;
			};
		};
	};
};

&tlmm {
	cam_main_reset_default: cam-main-reset-default-state {
		pins = "gpio118";
		function = "gpio";
		drive-strength = <2>;
		bias-disable;
	};

	cam_main_reset_sleep: cam-main-reset-sleep-state {
		pins = "gpio118";
		function = "gpio";
		drive-strength = <2>;
		bias-pull-down;
	};
};
